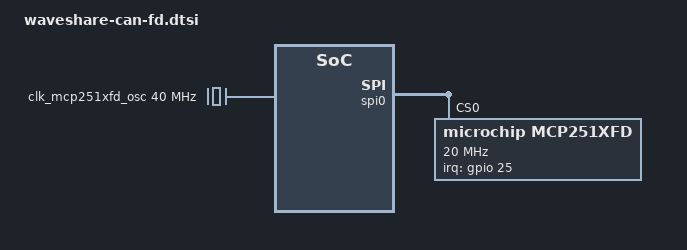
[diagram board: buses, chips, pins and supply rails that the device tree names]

&spidev0 {
	status = "disabled";
};

&gpio {
	mcp251xfd_pins: mcp251xfd_pins {
		brcm,pins = <25>;
		brcm,function = <BCM2835_FSEL_GPIO_IN>;
	};
};

/ {
	clocks {
		clk_mcp251xfd_osc: mcp251xfd-osc {
			#clock-cells = <0>;
			compatible = "fixed-clock";
			clock-frequency = <40000000>;
		};
	};
};

&spi0 {
	status = "okay";
	#address-cells = <1>;
	#size-cells = <0>;

	mcp251xfd: mcp251xfd@0 {
		compatible = "microchip,mcp251xfd";
		reg = <0>;
		pinctrl-names = "default";
		pinctrl-0 = <&mcp251xfd_pins>;
		spi-max-frequency = <20000000>;
		interrupt-parent = <&gpio>;
		interrupts = <25 IRQ_TYPE_LEVEL_LOW>;
		clocks = <&clk_mcp251xfd_osc>;
	};
};
